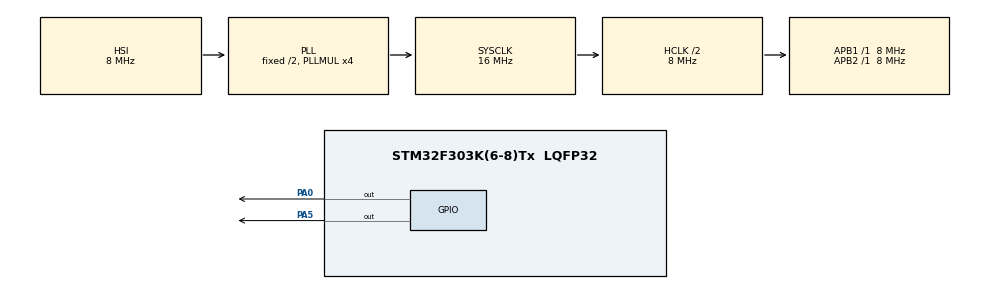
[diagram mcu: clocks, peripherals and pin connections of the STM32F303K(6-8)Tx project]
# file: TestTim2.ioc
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Mcu.Family=STM32F3
Mcu.Name=STM32F303K(6-8)Tx
Mcu.Package=LQFP32
NVIC.PriorityGroup=NVIC_PRIORITYGROUP_4
NVIC.TIM2_IRQn=true\:0\:0\:false\:false\:true\:true
NVIC.TIM3_IRQn=true\:0\:0\:false\:false\:true\:true
PA0.Signal=GPIO_Output
PA13.GPIO_Label=SWDIO
PA13.Mode=Trace_Asynchronous_SW
PA13.Signal=SYS_JTMS-SWDIO
PA14.GPIO_Label=SWCLK
PA14.Mode=Trace_Asynchronous_SW
PA14.Signal=SYS_JTCK-SWCLK
PA15.GPIO_Label=VCP_RX
PA15.Signal=USART2_RX
PA2.GPIO_Label=VCP_TX
PA2.Signal=USART2_TX
PA5.Signal=GPIO_Output
PB3.Mode=Trace_Asynchronous_SW
PB3.Signal=SYS_JTDO-TRACESWO
PF0\ /\ OSC_IN.GPIO_Label=MCO
PF0\ /\ OSC_IN.Signal=RCC_OSC_IN
ProjectManager.HeapSize=0x200
ProjectManager.StackSize=0x400
ProjectManager.TargetToolchain=TrueSTUDIO
RCC.AHBCLKDivider=RCC_SYSCLK_DIV2
RCC.AHBFreq_Value=8000000
RCC.APB1Freq_Value=8000000
RCC.APB1TimFreq_Value=8000000
RCC.APB2Freq_Value=8000000
RCC.APB2TimFreq_Value=8000000
RCC.CortexFreq_Value=8000000
RCC.HCLKFreq_Value=8000000
RCC.HSE_VALUE=8000000
RCC.HSI_VALUE=8000000
RCC.PLLMUL=RCC_PLL_MUL4
RCC.SYSCLKFreq_VALUE=16000000
RCC.SYSCLKSourceVirtual=RCC_SYSCLKSOURCE_PLLCLK
TIM2.Period=499
TIM2.Prescaler=15999
TIM3.Period=250
TIM3.Prescaler=15999
VP_TIM2_VS_ClockSourceINT.Mode=Internal
VP_TIM3_VS_ClockSourceINT.Mode=Internal
board=NUCLEO-F303K8

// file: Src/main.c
/**
  ******************************************************************************
  * @file           : main.c
  * @brief          : Main program body
  ******************************************************************************
  ** This notice applies to any and all portions of this file
  * that are not between comment pairs USER CODE BEGIN and
  * USER CODE END. Other portions of this file, whether
  * inserted by the user or by software development tools
  * are owned by their respective copyright owners.
  *
  * COPYRIGHT(c) 2018 STMicroelectronics
  *
  * Redistribution and use in source and binary forms, with or without modification,
  * are permitted provided that the following conditions are met:
  *   1. Redistributions of source code must retain the above copyright notice,
  *      this list of conditions and the following disclaimer.
  *   2. Redistributions in binary form must reproduce the above copyright notice,
  *      this list of conditions and the following disclaimer in the documentation
  *      and/or other materials provided with the distribution.
  *   3. Neither the name of STMicroelectronics nor the names of its contributors
  *      may be used to endorse or promote products derived from this software
  *      without specific prior written permission.
  *
  * THIS SOFTWARE IS PROVIDED BY THE COPYRIGHT HOLDERS AND CONTRIBUTORS "AS IS"
  * AND ANY EXPRESS OR IMPLIED WARRANTIES, INCLUDING, BUT NOT LIMITED TO, THE
  * IMPLIED WARRANTIES OF MERCHANTABILITY AND FITNESS FOR A PARTICULAR PURPOSE ARE
  * DISCLAIMED. IN NO EVENT SHALL THE COPYRIGHT HOLDER OR CONTRIBUTORS BE LIABLE
  * FOR ANY DIRECT, INDIRECT, INCIDENTAL, SPECIAL, EXEMPLARY, OR CONSEQUENTIAL
  * DAMAGES (INCLUDING, BUT NOT LIMITED TO, PROCUREMENT OF SUBSTITUTE GOODS OR
  * SERVICES; LOSS OF USE, DATA, OR PROFITS; OR BUSINESS INTERRUPTION) HOWEVER
  * CAUSED AND ON ANY THEORY OF LIABILITY, WHETHER IN CONTRACT, STRICT LIABILITY,
  * OR TORT (INCLUDING NEGLIGENCE OR OTHERWISE) ARISING IN ANY WAY OUT OF THE USE
  * OF THIS SOFTWARE, EVEN IF ADVISED OF THE POSSIBILITY OF SUCH DAMAGE.
  *
  ******************************************************************************
  */
#include "main.h"
#include "stm32f3xx_hal.h"

TIM_HandleTypeDef htim2;
TIM_HandleTypeDef htim3;

/* USER CODE BEGIN PV */
/* Private variables ---------------------------------------------------------*/

/* USER CODE END PV */

void SystemClock_Config(void);
static void MX_GPIO_Init(void);
static void MX_TIM2_Init(void);
static void MX_TIM3_Init(void);

/* USER CODE BEGIN PFP */
/* Private function prototypes -----------------------------------------------*/

/* USER CODE END PFP */

int main(void)
{

  /* MCU Configuration----------------------------------------------------------*/

  /* Reset of all peripherals, Initializes the Flash interface and the Systick. */
  HAL_Init();

  /* Configure the system clock */
  SystemClock_Config();

  /* Initialize all configured peripherals */
  MX_GPIO_Init();
  MX_TIM2_Init();
  MX_TIM3_Init();
  /* USER CODE BEGIN 2 */
  //Inicializamos el timer y la actv interrupcion
  HAL_TIM_Base_Start_IT(&htim2);
  HAL_TIM_Base_Start_IT(&htim3);
  /* USER CODE END 2 */

  /* Infinite loop */
  while (1)
  {

  }

}

void SystemClock_Config(void)
{

  RCC_OscInitTypeDef RCC_OscInitStruct;
  RCC_ClkInitTypeDef RCC_ClkInitStruct;

    /**Initializes the CPU, AHB and APB busses clocks
    */
  RCC_OscInitStruct.OscillatorType = RCC_OSCILLATORTYPE_HSI;
  RCC_OscInitStruct.HSIState = RCC_HSI_ON;
  RCC_OscInitStruct.HSICalibrationValue = 16;
  RCC_OscInitStruct.PLL.PLLState = RCC_PLL_ON;
  RCC_OscInitStruct.PLL.PLLSource = RCC_PLLSOURCE_HSI;
  RCC_OscInitStruct.PLL.PLLMUL = RCC_PLL_MUL4;
  if (HAL_RCC_OscConfig(&RCC_OscInitStruct) != HAL_OK)
  {
    _Error_Handler(__FILE__, __LINE__);
  }

    /**Initializes the CPU, AHB and APB busses clocks
    */
  RCC_ClkInitStruct.ClockType = RCC_CLOCKTYPE_HCLK|RCC_CLOCKTYPE_SYSCLK
                              |RCC_CLOCKTYPE_PCLK1|RCC_CLOCKTYPE_PCLK2;
  RCC_ClkInitStruct.SYSCLKSource = RCC_SYSCLKSOURCE_PLLCLK;
  RCC_ClkInitStruct.AHBCLKDivider = RCC_SYSCLK_DIV2;
  RCC_ClkInitStruct.APB1CLKDivider = RCC_HCLK_DIV1;
  RCC_ClkInitStruct.APB2CLKDivider = RCC_HCLK_DIV1;

  if (HAL_RCC_ClockConfig(&RCC_ClkInitStruct, FLASH_LATENCY_0) != HAL_OK)
  {
    _Error_Handler(__FILE__, __LINE__);
  }

    /**Configure the Systick interrupt time
    */
  HAL_SYSTICK_Config(HAL_RCC_GetHCLKFreq()/1000);

    /**Configure the Systick
    */
  HAL_SYSTICK_CLKSourceConfig(SYSTICK_CLKSOURCE_HCLK);

  /* SysTick_IRQn interrupt configuration */
  HAL_NVIC_SetPriority(SysTick_IRQn, 0, 0);
}

/* TIM2 init function */
static void MX_TIM2_Init(void)
{

  TIM_ClockConfigTypeDef sClockSourceConfig;
  TIM_MasterConfigTypeDef sMasterConfig;

  htim2.Instance = TIM2;
  htim2.Init.Prescaler = 15999;
  htim2.Init.CounterMode = TIM_COUNTERMODE_UP;
  htim2.Init.Period = 499;
  htim2.Init.ClockDivision = TIM_CLOCKDIVISION_DIV1;
  htim2.Init.AutoReloadPreload = TIM_AUTORELOAD_PRELOAD_DISABLE;
  if (HAL_TIM_Base_Init(&htim2) != HAL_OK)
  {
    _Error_Handler(__FILE__, __LINE__);
  }

  sClockSourceConfig.ClockSource = TIM_CLOCKSOURCE_INTERNAL;
  if (HAL_TIM_ConfigClockSource(&htim2, &sClockSourceConfig) != HAL_OK)
  {
    _Error_Handler(__FILE__, __LINE__);
  }

  sMasterConfig.MasterOutputTrigger = TIM_TRGO_RESET;
  sMasterConfig.MasterSlaveMode = TIM_MASTERSLAVEMODE_DISABLE;
  if (HAL_TIMEx_MasterConfigSynchronization(&htim2, &sMasterConfig) != HAL_OK)
  {
    _Error_Handler(__FILE__, __LINE__);
  }

}

/* TIM3 init function */
static void MX_TIM3_Init(void)
{

  TIM_ClockConfigTypeDef sClockSourceConfig;
  TIM_MasterConfigTypeDef sMasterConfig;

  htim3.Instance = TIM3;
  htim3.Init.Prescaler = 15999;
  htim3.Init.CounterMode = TIM_COUNTERMODE_UP;
  htim3.Init.Period = 249;
  htim3.Init.ClockDivision = TIM_CLOCKDIVISION_DIV1;
  htim3.Init.AutoReloadPreload = TIM_AUTORELOAD_PRELOAD_DISABLE;
  if (HAL_TIM_Base_Init(&htim3) != HAL_OK)
  {
    _Error_Handler(__FILE__, __LINE__);
  }

  sClockSourceConfig.ClockSource = TIM_CLOCKSOURCE_INTERNAL;
  if (HAL_TIM_ConfigClockSource(&htim3, &sClockSourceConfig) != HAL_OK)
  {
    _Error_Handler(__FILE__, __LINE__);
  }

  sMasterConfig.MasterOutputTrigger = TIM_TRGO_RESET;
  sMasterConfig.MasterSlaveMode = TIM_MASTERSLAVEMODE_DISABLE;
  if (HAL_TIMEx_MasterConfigSynchronization(&htim3, &sMasterConfig) != HAL_OK)
  {
    _Error_Handler(__FILE__, __LINE__);
  }

}

/** Configure pins as
        * Analog
        * Input
        * Output
        * EVENT_OUT
        * EXTI
     PA2   ------> USART2_TX
     PA15   ------> USART2_RX
*/
static void MX_GPIO_Init(void)
{

  GPIO_InitTypeDef GPIO_InitStruct;

  /* GPIO Ports Clock Enable */
  __HAL_RCC_GPIOF_CLK_ENABLE();
  __HAL_RCC_GPIOA_CLK_ENABLE();
  __HAL_RCC_GPIOB_CLK_ENABLE();

  /*Configure GPIO pin Output Level */
  HAL_GPIO_WritePin(GPIOA, GPIO_PIN_0|GPIO_PIN_5, GPIO_PIN_RESET);

  /*Configure GPIO pins : PA0 PA5 */
  GPIO_InitStruct.Pin = GPIO_PIN_0|GPIO_PIN_5;
  GPIO_InitStruct.Mode = GPIO_MODE_OUTPUT_PP;
  GPIO_InitStruct.Pull = GPIO_NOPULL;
  GPIO_InitStruct.Speed = GPIO_SPEED_FREQ_LOW;
  HAL_GPIO_Init(GPIOA, &GPIO_InitStruct);

  /*Configure GPIO pins : VCP_TX_Pin VCP_RX_Pin */
  GPIO_InitStruct.Pin = VCP_TX_Pin|VCP_RX_Pin;
  GPIO_InitStruct.Mode = GPIO_MODE_AF_PP;
  GPIO_InitStruct.Pull = GPIO_NOPULL;
  GPIO_InitStruct.Speed = GPIO_SPEED_FREQ_HIGH;
  GPIO_InitStruct.Alternate = GPIO_AF7_USART2;
  HAL_GPIO_Init(GPIOA, &GPIO_InitStruct);

}

/* USER CODE BEGIN 4 */
void HAL_TIM_PeriodElapsedCallback (TIM_HandleTypeDef * htim){
	if(htim->Instance == TIM2){
		HAL_GPIO_TogglePin(GPIOA,GPIO_PIN_0);
	}else if(htim->Instance ==TIM3){
		HAL_GPIO_TogglePin(GPIOA,GPIO_PIN_5);
	}
}
/* USER CODE END 4 */

void _Error_Handler(char *file, int line)
{
  while(1)
  {
  }
}

/************************ (C) COPYRIGHT STMicroelectronics *****END OF FILE****/
